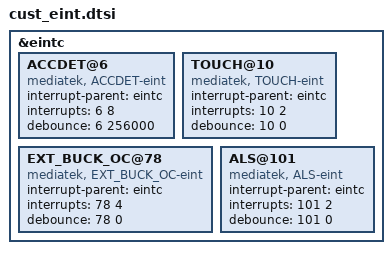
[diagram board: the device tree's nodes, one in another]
/*
 * Generated by MTK SP DrvGen Version 03.13.6 for MT6735M. Copyright MediaTek Inc. (C) 2013.
 * Fri Nov 18 16:17:02 2016
 * Do Not Modify the File.
 */

/*************************
 * EINT DTSI File
*************************/

&eintc {
	ACCDET@6 {
		compatible = "mediatek, ACCDET-eint";
		interrupt-parent = <&eintc>;
		interrupts = <6 8>;
		debounce = <6 256000>;
	};

	TOUCH@10 {
		compatible = "mediatek, TOUCH-eint";
		interrupt-parent = <&eintc>;
		interrupts = <10 2>;
		debounce = <10 0>;
	};

	EXT_BUCK_OC@78 {
		compatible = "mediatek, EXT_BUCK_OC-eint";
		interrupt-parent = <&eintc>;
		interrupts = <78 4>;
		debounce = <78 0>;
	};

	ALS@101 {
		compatible = "mediatek, ALS-eint";
		interrupt-parent = <&eintc>;
		interrupts = <101 2>;
		debounce = <101 0>;
	};

};
